AUTOSAR XML (schema 4-2-2)
# \copyright BMW AG 2017
package /BMW/Platform/Darh/SwComponentTypes
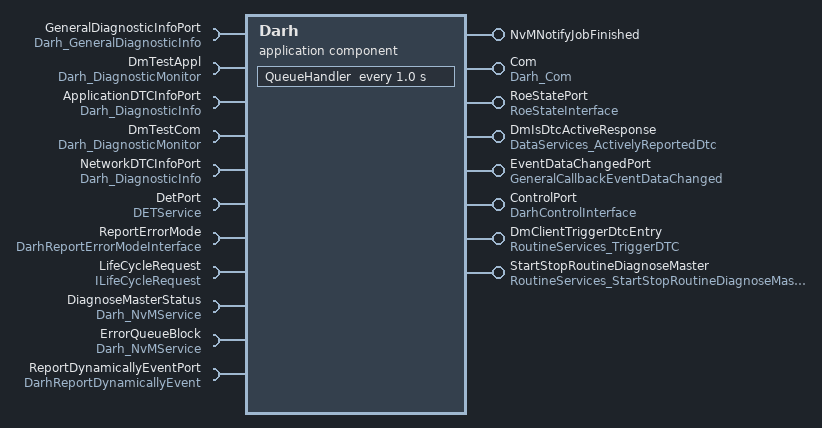
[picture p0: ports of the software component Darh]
  application sw component type Darh
    4 x provide port:
      NvMNotifyJobFinished: provided-interface=NvMNotifyJobFinished
      Com: provided-interface=Darh_Com
      RoeStatePort: provided-interface=RoeStateInterface
      DmIsDtcActiveResponse: provided-interface=DataServices_ActivelyReportedDtc
    5 x require port:
      GeneralDiagnosticInfoPort: required-interface=Darh_GeneralDiagnosticInfo
      DmTestAppl: required-interface=Darh_DiagnosticMonitor
      ApplicationDTCInfoPort: required-interface=Darh_DiagnosticInfo
      DmTestCom: required-interface=Darh_DiagnosticMonitor
      NetworkDTCInfoPort: required-interface=Darh_DiagnosticInfo
    provide port EventDataChangedPort: provided-interface=GeneralCallbackEventDataChanged
    require port DetPort: required-interface=DETService
    require port ReportErrorMode: required-interface=DarhReportErrorModeInterface
    provide port ControlPort: provided-interface=DarhControlInterface
    provide port DmClientTriggerDtcEntry: provided-interface=RoutineServices_TriggerDTC
    provide port StartStopRoutineDiagnoseMaster: provided-interface=RoutineServices_StartStopRoutineDiagnoseMaster
    require port LifeCycleRequest: nonqueued-receiver-com-spec{data-element=requestMode, init-value=DARH_STOPPED:2}, required-interface=ILifeCycleRequest
    provide/require port LifeCycle: mode-switch-sender-com-spec{enhanced-mode-api=true, mode-group=Mode, queue-length=2}, provided-required-interface=ILifeCycle
    require port DiagnoseMasterStatus: required-interface=Darh_NvMService
    require port ErrorQueueBlock: required-interface=Darh_NvMService
    require port ReportDynamicallyEventPort: required-interface=DarhReportDynamicallyEvent
    behavior InternalBehavior: data-type-mapping=[Darh_ModeRequestTypeMappings, Dcm_ModeRequestTypeMappings], handle-termination-and-restart=NO-SUPPORT, included-data-type-set=data-type=[Darh_SuspendedStateType, Darh_RoeStateType]
      exclusive area ExclusiveArea_0
      data received event LifeCycleRequest: start-on-event=LifeCycleHandler, data=LifeCycleRequest.requestMode
      operation invoked event E_WriteDataBlockNotification: start-on-event=WriteDataBlockNotification, operation=NvMNotifyJobFinished.JobFinished
      operation invoked event OperationInvokedEvent_SetRoeSuspended: start-on-event=SetRoeSuspended, operation=ControlPort.SetRoeSuspended
      operation invoked event OperationInvokedEvent_EventDataChanged: start-on-event=EventDataChanged, operation=EventDataChangedPort.EventDataChanged
      timing event TimingEvent: disabled-mode=[LifeCycle.Mode.DARH_INITIALIZED, LifeCycle.Mode.DARH_STOPPED], start-on-event=QueueHandler, period=1.0
      7 x operation invoked event:
        OperationInvokedEvent_ConditionCheckReadActivelyReportedDtc: start-on-event=ConditionCheckReadActivelyReportedDtc, operation=DmIsDtcActiveResponse.ConditionCheckRead
        OperationInvokedEvent_ReadActivelyReportedDtcLength: start-on-event=ReadActivelyReportedDtcLength, operation=DmIsDtcActiveResponse.ReadDataLength
        OperationInvokedEvent_ReadActivelyReportedDtc: start-on-event=ReadActivelyReportedDtc, operation=DmIsDtcActiveResponse.ReadData
        OperationInvokedEvent_StartRoutineTriggerDtc: start-on-event=StartRoutineTriggerDtc, operation=DmClientTriggerDtcEntry.Start
        OperationInvokedEvent_StartRoutineDiagnoseMaster: start-on-event=StartRoutineDiagnoseMaster, operation=StartStopRoutineDiagnoseMaster.Start
        OperationInvokedEvent_StopRoutineDiagnoseMaster: start-on-event=StopRoutineDiagnoseMaster, operation=StartStopRoutineDiagnoseMaster.Stop
        OperationInvokedEvent_GetRoeState: start-on-event=GetRoeState, operation=RoeStatePort.GetRoeState
      port-api-options:
        enable-take-address=false, indirect-api=false, port=DmTestAppl
        enable-take-address=false, indirect-api=false, port=EventDataChangedPort
        enable-take-address=false, indirect-api=false, port=NetworkDTCInfoPort
        enable-take-address=false, indirect-api=false, port=GeneralDiagnosticInfoPort
        enable-take-address=false, indirect-api=false, port=DmClientTriggerDtcEntry
        enable-take-address=false, indirect-api=false, port=ControlPort
        enable-take-address=false, indirect-api=false, port=DmTestCom
        enable-take-address=false, indirect-api=false, port=ApplicationDTCInfoPort
        enable-take-address=false, indirect-api=false, port=DmIsDtcActiveResponse
        enable-take-address=false, indirect-api=false, port=DetPort
        enable-take-address=false, indirect-api=false, port=ReportErrorMode
        enable-take-address=false, indirect-api=false, port=RoeStatePort
        enable-take-address=false, indirect-api=false, port=LifeCycleRequest
        enable-take-address=false, indirect-api=false, port=LifeCycle
        enable-take-address=false, indirect-api=false, port=ReportDynamicallyEventPort
      15 x runnable:
        WriteDataBlockNotification: can-be-invoked-concurrently=true, symbol=Darh_NvMNotifyJobFinishedDiagnoseMasterStatus
        LifeCycleHandler: can-enter-exclusive-area=ExclusiveArea_0, mode-access-point=LifeCycle.Mode, symbol=Darh_LifeCycleHandler
          data-read-access:
            access dra_ILifeCycleRequest_requestMode: accessed-variable=LifeCycleRequest.requestMode
          mode switch point LifeCycle: mode-group=LifeCycle.Mode
        QueueHandler: can-enter-exclusive-area=ExclusiveArea_0, symbol=Darh_ErrorQueueHandler
          data-send-points:
            access Com: accessed-variable=Com.data
          sync call DetPort_ReportError: operation=DetPort.ReportError, timeout=0
        SetRoeSuspended: can-be-invoked-concurrently=true, symbol=Darh_SetRoeSuspendedHandler
          sync call DetPort_ReportError: operation=DetPort.ReportError, timeout=0
        EventDataChanged: can-enter-exclusive-area=ExclusiveArea_0, symbol=Darh_EventDataChangedHandler
          4 x sync call, all with timeout=0:
            DetPort_ReportError: operation=DetPort.ReportError
            GeneralDiag_GetFreezeFrameData: operation=GeneralDiagnosticInfoPort.GetEventFreezeFrameData
            ErrorQueueBlock_SetRamBlockStatus: operation=ErrorQueueBlock.SetRamBlockStatus
            ReportDynamicallyEventPort_EventToReport: operation=ReportDynamicallyEventPort.EventToReport
        ConditionCheckRead: can-be-invoked-concurrently=true, mode-access-point=LifeCycle.Mode, symbol=Darh_ConditionCheckReadErrorQueueHandler
          sync call DetPort_ReportError: operation=DetPort.ReportError, timeout=0
        ReadErrorQueueLength: can-enter-exclusive-area=ExclusiveArea_0, symbol=Darh_ReadErrorQueueLengthHandler
          sync call DetPort_ReportError: operation=DetPort.ReportError, timeout=0
        ReadErrorQueue: can-enter-exclusive-area=ExclusiveArea_0, symbol=Darh_ReadErrorQueueDataHandler
          sync call GeneralDiag_GetDTCOfEvent: operation=GeneralDiagnosticInfoPort.GetDTCOfEvent, timeout=0
          sync call DetPort_ReportError: operation=DetPort.ReportError, timeout=0
        ConditionCheckReadActivelyReportedDtc: can-be-invoked-concurrently=true, mode-access-point=LifeCycle.Mode, symbol=Darh_ConditionCheckReadActivelyReportedDtcHandler
          sync call DetPort_ReportError: operation=DetPort.ReportError, timeout=0
        ReadActivelyReportedDtcLength: symbol=Darh_ReadActivelyReportedDtcLengthHandler
          sync call DetPort_ReportError: operation=DetPort.ReportError, timeout=0
          sync call ReportDynamicallyEventPort_EventToReportCount: operation=ReportDynamicallyEventPort.EventToReportCount, timeout=0
        ReadActivelyReportedDtc: symbol=Darh_ReadActivelyReportedDtcDataHandler
          5 x sync call, all with timeout=0:
            DetPort_ReportError: operation=DetPort.ReportError
            GeneralDiag_GetDTCOfEvent: operation=GeneralDiagnosticInfoPort.GetDTCOfEvent
            ReportDynamicallyEventPort_EventToReport: operation=ReportDynamicallyEventPort.EventToReport
            ReportDynamicallyEventPort_EventIdx2EventId: operation=ReportDynamicallyEventPort.EventIdx2EventId
            ReportDynamicallyEventPort_EventToReportCount: operation=ReportDynamicallyEventPort.EventToReportCount
        StartRoutineTriggerDtc: symbol=Darh_StartRoutineTriggerDtcHandler
          5 x sync call, all with timeout=0:
            DetPort_ReportError: operation=DetPort.ReportError
            DmTestCom_SetEventStatus: operation=DmTestCom.SetEventStatus
            ApplicationDTC_GetDTCOfEvent: operation=ApplicationDTCInfoPort.GetDTCOfEvent
            NetworkDTCInfo_GetDTCOfEvent: operation=NetworkDTCInfoPort.GetDTCOfEvent
            ApplicationDTC_GetEvtStatus: operation=DmTestAppl.SetEventStatus
        StartRoutineDiagnoseMaster: symbol=Darh_StartRoutineDiagnoseMasterHandler
          sync call DiagnoseMasterStatus_WriteBlock: operation=DiagnoseMasterStatus.WriteBlock, timeout=0
        StopRoutineDiagnoseMaster: symbol=Darh_StopRoutineDiagnoseMasterHandler
          sync call DiagnoseMasterStatus_WriteBlock: operation=DiagnoseMasterStatus.WriteBlock, timeout=0
        GetRoeState: can-enter-exclusive-area=ExclusiveArea_0, can-be-invoked-concurrently=true, symbol=Darh_ReadRoeStateDataHandler
          sync call DetPort_ReportError: operation=DetPort.ReportError, timeout=0
      6 x swc service dependency:
        DarhNvmServiceNeed: assigned-ports=role-based-port-assignment={port-prototype=ErrorQueueBlock, role=NvMService}
          service-needs:
            nv block needs sn_DarhNvmServiceNeed: n-data-sets=1, restore-at-start=true, store-at-shutdown=true
        DarhNvmAddressServiceNeed: assigned-ports=role-based-port-assignment={port-prototype=DiagnoseMasterStatus, role=NvMService}
          service-needs:
            nv block needs sn_DarhNvmAddressServiceNeed: n-data-sets=1, restore-at-start=true, store-at-shutdown=false
        DarhDcmServiceNeeds
          assigned-ports:
            port-prototype=DmClientTriggerDtcEntry, role=RoutineServices
            port-prototype=StartStopRoutineDiagnoseMaster, role=RoutineServices
            port-prototype=DmIsDtcActiveResponse, role=DataServices
          service-needs:
            diagnostic communication manager needs sn_DarhDcmServiceNeeds
        DemServiceNeeds
          assigned-ports:
            port-prototype=EventDataChangedPort, role=GeneralCallbackEventDataChanged
            port-prototype=GeneralDiagnosticInfoPort, role=GeneralDiagnosticInfo
          service-needs:
            diagnostic event manager needs sn_DemServiceNeeds
        DarhDummyNetworkDtcServiceNeeds  # DTC vale shall be set to: 0xC90400 + (0x4000 * ECUDiagnosticAddress) + 0x07FF Event destination: primary origin Event kind: DEM_EVENT_KIND_SWC Description: Dummy Network DTC
          assigned-ports:
            port-prototype=DmTestCom, role=Darh_DiagnosticMonitor
            port-prototype=NetworkDTCInfoPort, role=DiagnosticInfo
          service-needs:
            diagnostic event needs sn_DarhDtcServiceNeeds: consider-pto-status=false, dtc-kind=NON-EMMISSION-RELATED-DTC
              diag-event-debounce-algorithm:
                diag event debounce monitor internal InternalDebounce
        DarhDummyApplicationDtcServiceNeeds  # DTC vale shall be set to: 0x02FF00 + ECUDiagnosticAddress Event destination: primary origin Event kind: DEM_EVENT_KIND_SWC Description: Dummy Application DTC
          assigned-ports:
            port-prototype=DmTestAppl, role=Darh_DiagnosticMonitor
            port-prototype=ApplicationDTCInfoPort, role=DiagnosticInfo
          service-needs:
            diagnostic event needs sn_DarhApplicationDtcServiceNeeds: consider-pto-status=false, dtc-kind=NON-EMMISSION-RELATED-DTC
              diag-event-debounce-algorithm:
                diag event debounce monitor internal InternalDebounce
package /BMW/Platform/Darh/SwcImplementations
  swc implementation Darh_Implementation: programming-language=C, sw-version=5.1.0, vendor-id=5, behavior=InternalBehavior
    code-descriptors:
      code CodeDescriptor: artifact-descriptors=autosar-engineering-object={short-label=EngObject, category=SWSRC}
    resource consumption Resources
